# MK65F18 register map
Vendor: Freescale Semiconductor, Inc.; Series: Kinetis_K; File version: 1.6
CPU: CM4 r0p1, little endian, no MPU, FPU, VTOR, 4 interrupt priority bits
Registers are 32-bit, read-write, reset 0x0 unless marked. A register's access mark holds for its fields unless they carry their own. Offsets are from the block's base; [hi:lo] are bit positions; {n}, {i} and the like mark numbered series.

## USBDCD — USB Device Charger Detection module
Base 0x40035000; register names take the prefix USBDCD_
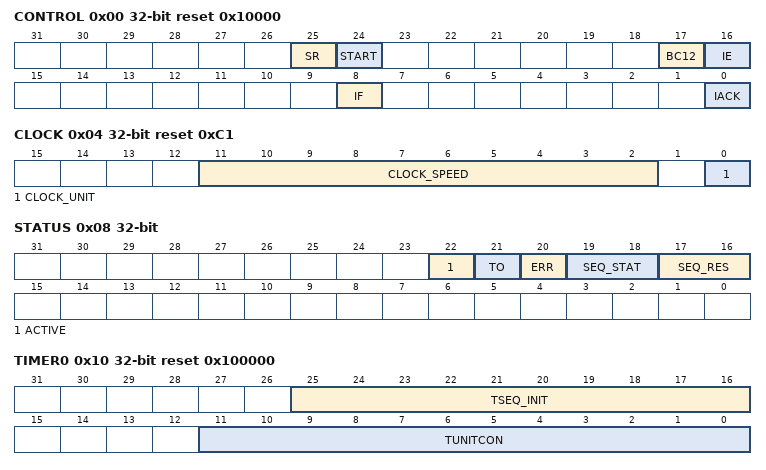
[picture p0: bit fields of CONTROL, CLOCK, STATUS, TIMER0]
0x00 CONTROL reset 0x10000
  [25] SR wo — Software Reset
    0=Do not perform a software reset; 1=Perform a software reset
  [24] START wo — Start Change Detection Sequence
    0=Do not start the sequence. Writes of this value have no effect.; 1=Initiate the charger detection sequence. If the sequence is already running, writes of this value have no effect.
  [17] BC12 — BC1.2 compatibility. This bit cannot be changed after start detection.
    0=Compatible with BC1.1 (default); 1=Compatible with BC1.2
  [16] IE — Interrupt Enable
    0=Disable interrupts to the system; 1=Enable interrupts to the system
  [8] IF ro — Interrupt Flag
    0=No interrupt is pending; 1=An interrupt is pending
  [0] IACK wo — Interrupt Acknowledge
    0=Do not clear the interrupt; 1=Clear the IF bit (interrupt flag)
0x04 CLOCK reset 0xC1
  [11:2] CLOCK_SPEED — Numerical Value of Clock Speed in Binary
  [0] CLOCK_UNIT — Unit of Measurement Encoding for Clock Speed
    0=kHz Speed (between 1 kHz and 1023 kHz); 1=MHz Speed (between 1 MHz and 1023 MHz)
0x08 STATUS ro
  [22] ACTIVE — Active Status Indicator
    0=The sequence is not running; 1=The sequence is running
  [21] TO — Timeout Flag
    0=The detection sequence has not been running for over 1 s; 1=It has been over 1 s since the data pin contact was detected and debounced
  [20] ERR — Error Flag
    0=No sequence errors; 1=Error in the detection sequence. See the SEQ_STAT field to determine the phase in which the error occurred.
  [19:18] SEQ_STAT — Charger Detection Sequence Status
    0=The module is either not enabled, or the module is enabled but the data pins have not yet been detected; 1=Data pin contact detection is complete; 2=Charging port detection is complete; 3=Charger type detection is complete
  [17:16] SEQ_RES — Charger Detection Sequence Results
    0=No results to report; 1=Attached to an SDP. Must comply with USB 2.0 by drawing only 2.5 mA (max) until connected.; 2=Attached to a charging port. The exact meaning depends on bit 18: 0: Attached to either a CDP or a DCP. The charger type detection has not completed. 1: Attached to a CDP. The charger type detection has completed.; 3=Attached to a DCP
0x0C SIGNAL_OVERRIDE
  [1:0] PS — Phase Selection
    0=No overrides. Bit field must remain at this value during normal USB data communication to prevent unexpected conditions on USB_DP and USB_DM pins. (Default); 1=Reserved, not for customer use; 2=Enables VDP_SRC voltage source for the USB_DP pin and IDM_SINK current source for the USB_DM pin; 3=Reserved, not for customer use
0x10 TIMER0 reset 0x100000
  [25:16] TSEQ_INIT — Sequence Initiation Time
  [11:0] TUNITCON ro — Unit Connection Timer Elapse (in ms)
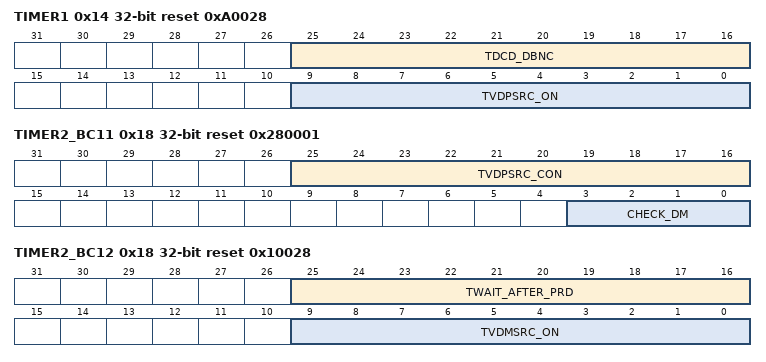
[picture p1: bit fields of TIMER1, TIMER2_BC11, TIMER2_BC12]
0x14 TIMER1 reset 0xA0028
  [25:16] TDCD_DBNC — Time Period to Debounce D+ Signal
  [9:0] TVDPSRC_ON — Time Period Comparator Enabled
0x18 TIMER2_BC11 reset 0x280001 (USBDCD view)
  [25:16] TVDPSRC_CON — Time Period Before Enabling D+ Pullup
  [3:0] CHECK_DM — Time Before Check of D- Line
0x18 TIMER2_BC12 reset 0x10028 (USBDCD view)
  [25:16] TWAIT_AFTER_PRD — Sets the amount of time (in ms) that the module waits after primary detection before start to secondary detection
  [9:0] TVDMSRC_ON — Sets the amount of time (in ms) that the module enables the VDM_SRC. Valid values are 0-40ms.

## USBHSDCD — USB Device Charger Detection module
Base 0x400A3000; register names take the prefix USBHSDCD_
Registers as USBDCD (with USBDCD read as USBHSDCD).

## PIT — Periodic Interrupt Timer
Base 0x40037000; register names take the prefix PIT_
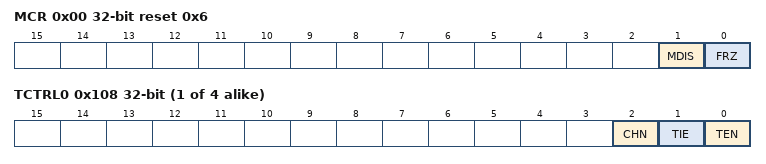
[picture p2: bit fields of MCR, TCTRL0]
0x00 MCR reset 0x6 — PIT Module Control Register
  [1] MDIS — Module Disable - (PIT section)
    0=Clock for standard PIT timers is enabled; 1=Clock for standard PIT timers is disabled
  [0] FRZ — Freeze
    0=Timers continue to run in Debug mode; 1=Timers are stopped in Debug mode
0xE0 LTMR64H ro — PIT Upper Lifetime Timer Register
  [31:0] LTH — Life Timer value
0xE4 LTMR64L ro — PIT Lower Lifetime Timer Register
  [31:0] LTL — Life Timer value
{0x100+0x10*i} LDVAL{i} (i=0..3) — Timer Load Value Register
  [31:0] TSV — Timer Start Value
{0x104+0x10*i} CVAL{i} (i=0..3) ro — Current Timer Value Register
  [31:0] TVL — Current Timer Value
{0x108+0x10*i} TCTRL{i} (i=0..3) — Timer Control Register
  [2] CHN — Chain Mode
    0=Timer is not chained; 1=Timer is chained to previous timer. For example, for Channel 2, if this field is set, Timer 2 is chained to Timer 1.
  [1] TIE — Timer Interrupt Enable
    0=Interrupt requests from Timer n are disabled; 1=Interrupt will be requested whenever TIF is set
  [0] TEN — Timer Enable
    0=Timer n is disabled; 1=Timer n is enabled
{0x10C+0x10*i} TFLG{i} (i=0..3) — Timer Flag Register
  [0] TIF — Timer Interrupt Flag
    0=Timeout has not yet occurred; 1=Timeout has occurred

## Notices in the file
Redistribution and use in source and binary forms, with or without modification,
are permitted provided that the following conditions are met:
o Redistributions of source code must retain the above copyright notice, this list
of conditions and the following disclaimer.
o Redistributions in binary form must reproduce the above copyright notice, this
list of conditions and the following disclaimer in the documentation and/or
other materials provided with the distribution.
o Neither the name of Freescale Semiconductor, Inc. nor the names of its
contributors may be used to endorse or promote products derived from this
software without specific prior written permission.
THIS SOFTWARE IS PROVIDED BY THE COPYRIGHT HOLDERS AND CONTRIBUTORS "AS IS" AND
ANY EXPRESS OR IMPLIED WARRANTIES, INCLUDING, BUT NOT LIMITED TO, THE IMPLIED
WARRANTIES OF MERCHANTABILITY AND FITNESS FOR A PARTICULAR PURPOSE ARE
DISCLAIMED. IN NO EVENT SHALL THE COPYRIGHT HOLDER OR CONTRIBUTORS BE LIABLE FOR
ANY DIRECT, INDIRECT, INCIDENTAL, SPECIAL, EXEMPLARY, OR CONSEQUENTIAL DAMAGES
(INCLUDING, BUT NOT LIMITED TO, PROCUREMENT OF SUBSTITUTE GOODS OR SERVICES;
LOSS OF USE, DATA, OR PROFITS; OR BUSINESS INTERRUPTION) HOWEVER CAUSED AND ON
ANY THEORY OF LIABILITY, WHETHER IN CONTRACT, STRICT LIABILITY, OR TORT
(INCLUDING NEGLIGENCE OR OTHERWISE) ARISING IN ANY WAY OUT OF THE USE OF THIS
SOFTWARE, EVEN IF ADVISED OF THE POSSIBILITY OF SUCH DAMAGE.
